# HC32F472 register map
File version: 1.0
CPU: CM4 r0p1, little endian, MPU, FPU, 4 interrupt priority bits
Registers are 32-bit, read-write, reset 0x0 unless marked. A register's access mark holds for its fields unless they carry their own. Offsets are from the block's base; [hi:lo] are bit positions; {n}, {i} and the like mark numbered series.

## TMR61 — desc TMR6
Base 0x4003C000
Same registers: TMR{n} {0x4002CC00+0x400*n} (n=62..69), TMR610 0x4003E400
0x00 CNTER (reset mask 0xFFFF)
0x04 UPDAR (reset mask 0xFFFF)
0x40 PERAR reset 0xFFFFFFFF (reset mask 0xFFFF)
0x44 PERBR reset 0xFFFFFFFF (reset mask 0xFFFF)
0x48 PERCR reset 0xFFFFFFFF (reset mask 0xFFFF)
0x80 GCMAR reset 0xFFFFFFFF (reset mask 0xFFFF)
0x84 GCMBR reset 0xFFFFFFFF (reset mask 0xFFFF)
0x88 GCMCR reset 0xFFFFFFFF (reset mask 0xFFFF)
0x8C GCMDR reset 0xFFFFFFFF (reset mask 0xFFFF)
0x90 GCMER reset 0xFFFFFFFF (reset mask 0xFFFF)
0x94 GCMFR reset 0xFFFFFFFF (reset mask 0xFFFF)
0xC0 SCMAR reset 0xFFFFFFFF (reset mask 0xFFFF)
0xC4 SCMBR reset 0xFFFFFFFF (reset mask 0xFFFF)
0xC8 SCMCR reset 0xFFFFFFFF (reset mask 0xFFFF)
0xCC SCMDR reset 0xFFFFFFFF (reset mask 0xFFFF)
0xD0 SCMER reset 0xFFFFFFFF (reset mask 0xFFFF)
0xD4 SCMFR reset 0xFFFFFFFF (reset mask 0xFFFF)
0x100 DTUAR reset 0xFFFFFFFF (reset mask 0xFFFF)
0x104 DTDAR reset 0xFFFFFFFF (reset mask 0xFFFF)
0x108 DTUBR reset 0xFFFFFFFF (reset mask 0xFFFF)
0x10C DTDBR reset 0xFFFFFFFF (reset mask 0xFFFF)
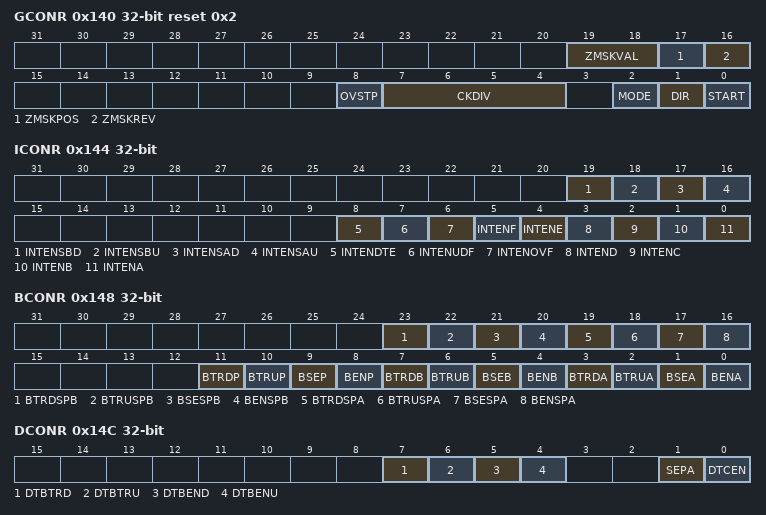
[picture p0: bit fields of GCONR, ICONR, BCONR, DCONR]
0x140 GCONR reset 0x2
  [19:18] ZMSKVAL, [17] ZMSKPOS, [16] ZMSKREV, [8] OVSTP, [7:4] CKDIV, [2] MODE, [1] DIR, [0] START
0x144 ICONR
  [19] INTENSBD, [18] INTENSBU, [17] INTENSAD, [16] INTENSAU, [8] INTENDTE, [7] INTENUDF, [6] INTENOVF, [5] INTENF, [4] INTENE, [3] INTEND, [2] INTENC, [1] INTENB, [0] INTENA
0x148 BCONR
  [23] BTRDSPB, [22] BTRUSPB, [21] BSESPB, [20] BENSPB, [19] BTRDSPA, [18] BTRUSPA, [17] BSESPA, [16] BENSPA, [11] BTRDP, [10] BTRUP, [9] BSEP, [8] BENP, [7] BTRDB, [6] BTRUB, [5] BSEB, [4] BENB, [3] BTRDA, [2] BTRUA, [1] BSEA, [0] BENA
0x14C DCONR
  [7] DTBTRD, [6] DTBTRU, [5] DTBEND, [4] DTBENU, [1] SEPA, [0] DTCEN
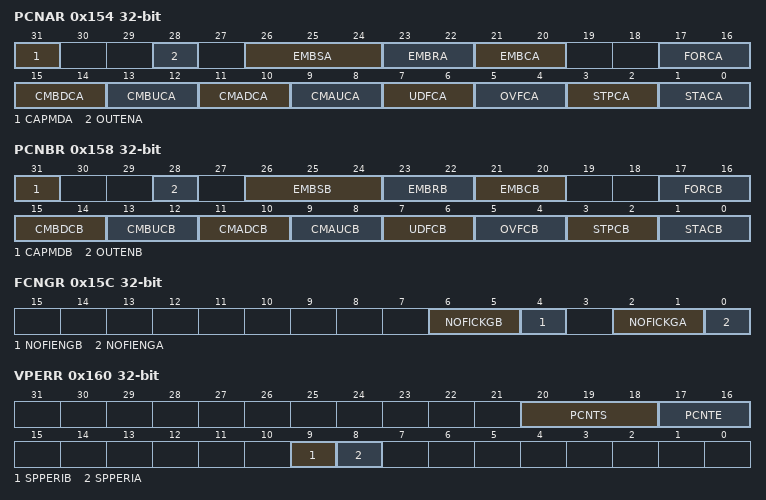
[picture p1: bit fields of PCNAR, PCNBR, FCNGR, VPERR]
0x154 PCNAR
  [31] CAPMDA, [28] OUTENA, [26:24] EMBSA, [23:22] EMBRA, [21:20] EMBCA, [17:16] FORCA, [15:14] CMBDCA, [13:12] CMBUCA, [11:10] CMADCA, [9:8] CMAUCA, [7:6] UDFCA, [5:4] OVFCA, [3:2] STPCA, [1:0] STACA
0x158 PCNBR
  [31] CAPMDB, [28] OUTENB, [26:24] EMBSB, [23:22] EMBRB, [21:20] EMBCB, [17:16] FORCB, [15:14] CMBDCB, [13:12] CMBUCB, [11:10] CMADCB, [9:8] CMAUCB, [7:6] UDFCB, [5:4] OVFCB, [3:2] STPCB, [1:0] STACB
0x15C FCNGR
  [6:5] NOFICKGB, [4] NOFIENGB, [2:1] NOFICKGA, [0] NOFIENGA
0x160 VPERR
  [20:18] PCNTS, [17:16] PCNTE, [9] SPPERIB, [8] SPPERIA
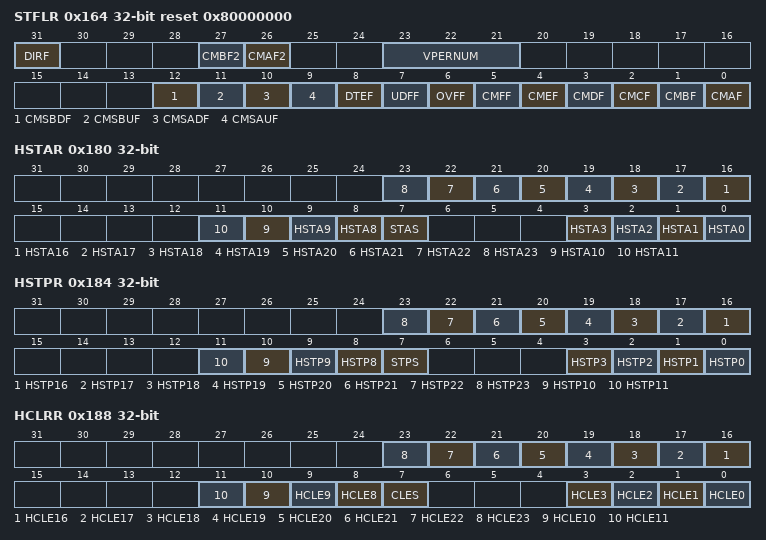
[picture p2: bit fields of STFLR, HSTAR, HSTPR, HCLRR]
0x164 STFLR reset 0x80000000
  [31] DIRF ro, [27] CMBF2, [26] CMAF2, [23:21] VPERNUM ro, [12] CMSBDF, [11] CMSBUF, [10] CMSADF, [9] CMSAUF, [8] DTEF ro, [7] UDFF, [6] OVFF, [5] CMFF, [4] CMEF, [3] CMDF, [2] CMCF, [1] CMBF, [0] CMAF
0x180 HSTAR
  [n] HSTA{n} (n=16..23), [n] HSTA{n} (n=8..11), [7] STAS, [n] HSTA{n} (n=0..3)
0x184 HSTPR
  [n] HSTP{n} (n=16..23), [n] HSTP{n} (n=8..11), [7] STPS, [n] HSTP{n} (n=0..3)
0x188 HCLRR
  [n] HCLE{n} (n=16..23), [n] HCLE{n} (n=8..11), [7] CLES, [n] HCLE{n} (n=0..3)
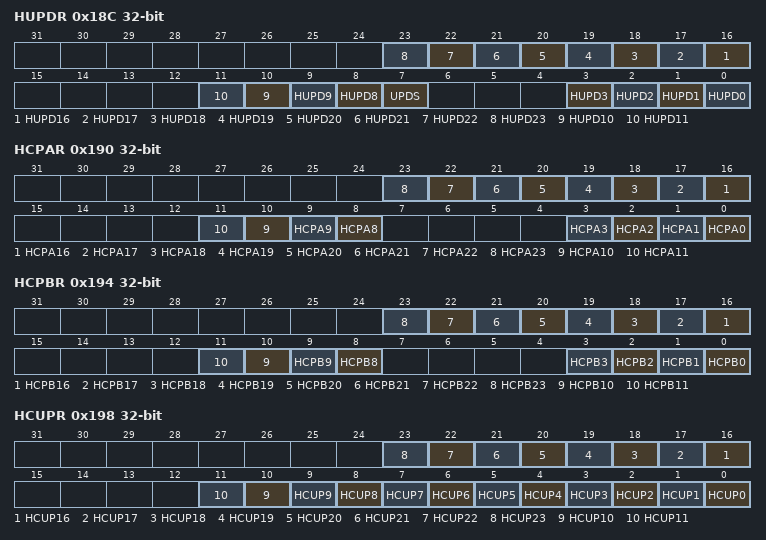
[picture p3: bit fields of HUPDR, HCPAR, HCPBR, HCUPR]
0x18C HUPDR
  [n] HUPD{n} (n=16..23), [n] HUPD{n} (n=8..11), [7] UPDS, [n] HUPD{n} (n=0..3)
0x190 HCPAR
  [n] HCPA{n} (n=16..23), [n] HCPA{n} (n=8..11), [n] HCPA{n} (n=0..3)
0x194 HCPBR
  [n] HCPB{n} (n=16..23), [n] HCPB{n} (n=8..11), [n] HCPB{n} (n=0..3)
0x198 HCUPR
  [n] HCUP{n} (n=16..23), [n] HCUP{n} (n=0..11)
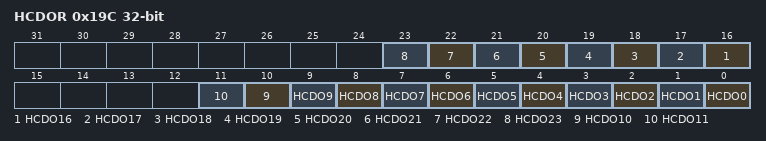
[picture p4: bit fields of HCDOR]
0x19C HCDOR
  [n] HCDO{n} (n=16..23), [n] HCDO{n} (n=0..11)

## TMR6_COMMON
Base 0x4003C300
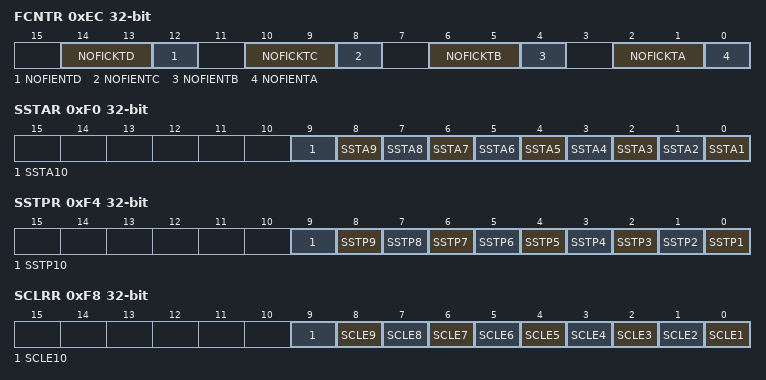
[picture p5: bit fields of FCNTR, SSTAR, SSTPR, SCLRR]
0xEC FCNTR
  [14:13] NOFICKTD, [12] NOFIENTD, [10:9] NOFICKTC, [8] NOFIENTC, [6:5] NOFICKTB, [4] NOFIENTB, [2:1] NOFICKTA, [0] NOFIENTA
0xF0 SSTAR
  [n-1] SSTA{n} (n=1..10)
0xF4 SSTPR
  [n-1] SSTP{n} (n=1..10)
0xF8 SCLRR
  [n-1] SCLE{n} (n=1..10)
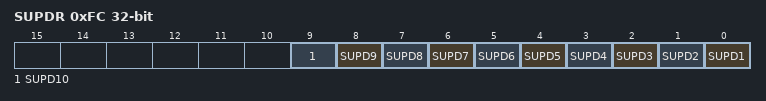
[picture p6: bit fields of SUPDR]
0xFC SUPDR
  [n-1] SUPD{n} (n=1..10)

## TMRA1
Base 0x4003A000
Same registers: TMRA2 0x4003A400
0x00 CNTER
0x04 PERAR reset 0xFFFFFFFF
{0x3C+4i} CMPAR{i} reset 0xFFFFFFFF (i=1..4)
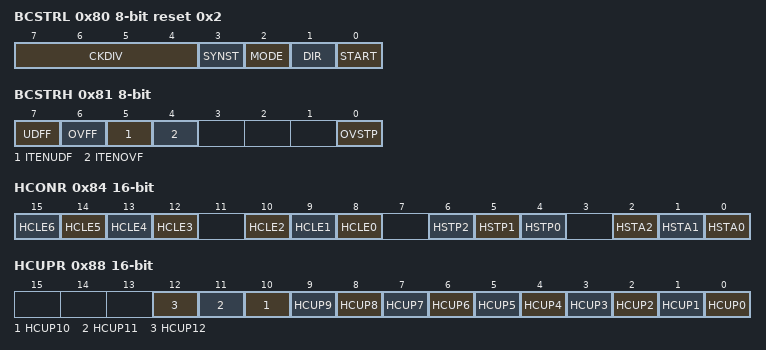
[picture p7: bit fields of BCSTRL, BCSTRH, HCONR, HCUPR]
0x80 BCSTRL 8-bit reset 0x2
  [7:4] CKDIV, [3] SYNST, [2] MODE, [1] DIR, [0] START
0x81 BCSTRH 8-bit
  [7] UDFF, [6] OVFF, [5] ITENUDF, [4] ITENOVF, [0] OVSTP
0x84 HCONR 16-bit
  [n+9] HCLE{n} (n=3..6), [10] HCLE2, [9] HCLE1, [8] HCLE0, [6] HSTP2, [5] HSTP1, [4] HSTP0, [2] HSTA2, [1] HSTA1, [0] HSTA0
0x88 HCUPR 16-bit
  [n] HCUP{n} (n=0..12)
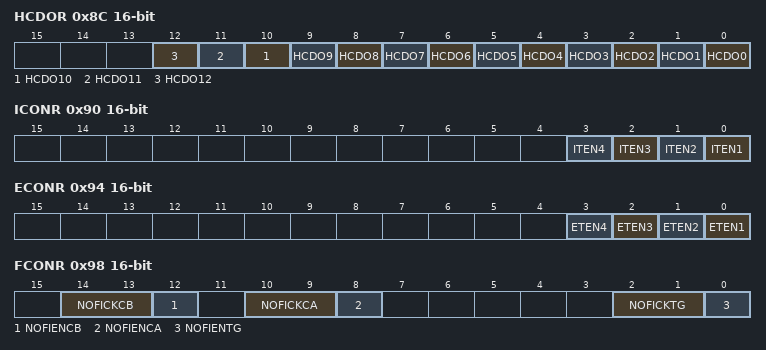
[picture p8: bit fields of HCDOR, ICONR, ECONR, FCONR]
0x8C HCDOR 16-bit
  [n] HCDO{n} (n=0..12)
0x90 ICONR 16-bit
  [n-1] ITEN{n} (n=1..4)
0x94 ECONR 16-bit
  [n-1] ETEN{n} (n=1..4)
0x98 FCONR 16-bit
  [14:13] NOFICKCB, [12] NOFIENCB, [10:9] NOFICKCA, [8] NOFIENCA, [2:1] NOFICKTG, [0] NOFIENTG
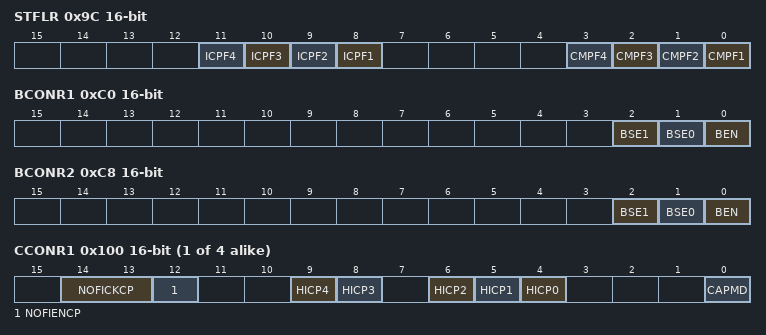
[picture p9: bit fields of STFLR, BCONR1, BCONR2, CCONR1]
0x9C STFLR 16-bit
  [n+7] ICPF{n} (n=1..4), [n-1] CMPF{n} (n=1..4)
0xC0 BCONR1 16-bit
  [2] BSE1, [1] BSE0, [0] BEN
0xC8 BCONR2 16-bit
  [2] BSE1, [1] BSE0, [0] BEN
{0xFC+4i} CCONR{i} 16-bit (i=1..4)
  [14:13] NOFICKCP, [12] NOFIENCP, [9] HICP4, [8] HICP3, [6] HICP2, [5] HICP1, [4] HICP0, [0] CAPMD
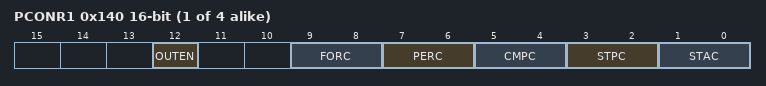
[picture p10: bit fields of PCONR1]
{0x13C+4i} PCONR{i} 16-bit (i=1..4)
  [12] OUTEN, [9:8] FORC, [7:6] PERC, [5:4] CMPC, [3:2] STPC, [1:0] STAC

## TMRA3
Base 0x4003A800
Same registers: TMRA5 0x40026000, TMRA6 0x40026400, TMRA4 0x4003AC00
Registers as TMRA1; these are added or differ:
0x00 CNTER 16-bit
0x04 PERAR 16-bit reset 0xFFFF
{0x3C+4i} CMPAR{i} 16-bit reset 0xFFFF (i=1..4)

## TRNG
Base 0x40042000
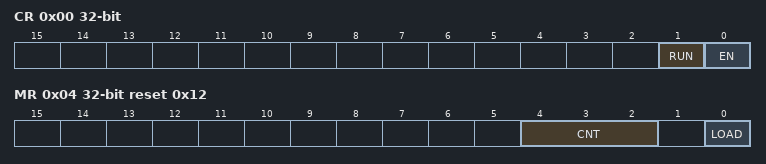
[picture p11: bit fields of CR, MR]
0x00 CR
  [1] RUN, [0] EN
0x04 MR reset 0x12
  [4:2] CNT, [0] LOAD
0x0C DR0 ro reset 0x8000000
0x10 DR1 ro reset 0x8000200

## USART1
Base 0x4001CC00
Same registers: USART2 0x4001D000, USART4 0x40020C00, USART5 0x40021000
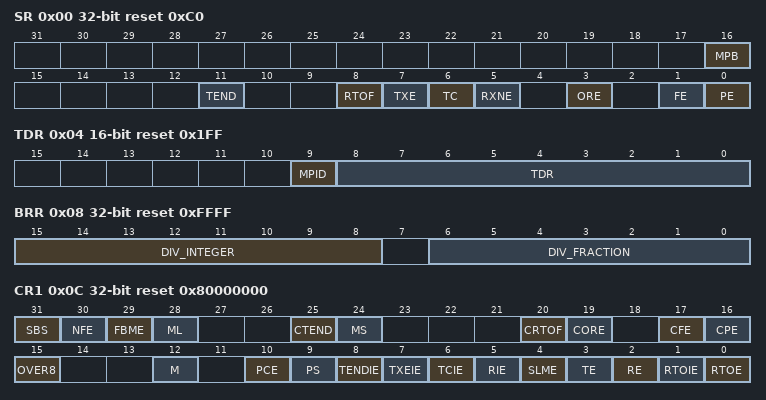
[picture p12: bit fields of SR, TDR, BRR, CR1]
0x00 SR ro reset 0xC0
  [16] MPB, [11] TEND, [8] RTOF, [7] TXE, [6] TC, [5] RXNE, [3] ORE, [1] FE, [0] PE
0x04 TDR 16-bit reset 0x1FF
  [9] MPID, [8:0] TDR
0x06 RDR 16-bit ro
  [8:0] RDR
0x08 BRR reset 0xFFFF
  [15:8] DIV_INTEGER, [6:0] DIV_FRACTION
0x0C CR1 reset 0x80000000
  [31] SBS, [30] NFE, [29] FBME, [28] ML, [25] CTEND, [24] MS, [20] CRTOF, [19] CORE, [17] CFE, [16] CPE, [15] OVER8, [12] M, [10] PCE, [9] PS, [8] TENDIE, [7] TXEIE, [6] TCIE, [5] RIE, [4] SLME, [3] TE, [2] RE, [1] RTOIE, [0] RTOE
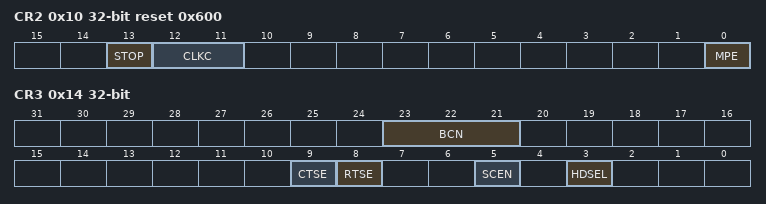
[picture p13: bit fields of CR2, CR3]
0x10 CR2 reset 0x600
  [13] STOP, [12:11] CLKC, [0] MPE
0x14 CR3
  [23:21] BCN, [9] CTSE, [8] RTSE, [5] SCEN, [3] HDSEL
0x18 PR
  [1:0] PSC

## USART3
Base 0x4001D400
Same registers: USART6 0x40021400
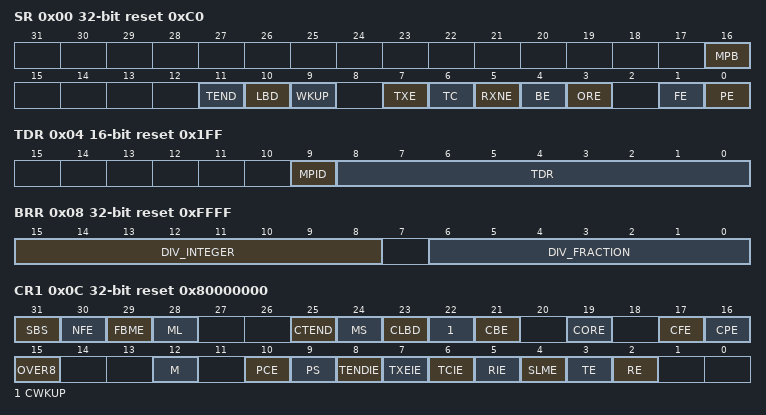
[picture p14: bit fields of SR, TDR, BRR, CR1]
0x00 SR ro reset 0xC0
  [16] MPB, [11] TEND, [10] LBD, [9] WKUP, [7] TXE, [6] TC, [5] RXNE, [4] BE, [3] ORE, [1] FE, [0] PE
0x04 TDR 16-bit reset 0x1FF
  [9] MPID, [8:0] TDR
0x06 RDR 16-bit ro
  [8:0] RDR
0x08 BRR reset 0xFFFF
  [15:8] DIV_INTEGER, [6:0] DIV_FRACTION
0x0C CR1 reset 0x80000000
  [31] SBS, [30] NFE, [29] FBME, [28] ML, [25] CTEND, [24] MS, [23] CLBD, [22] CWKUP, [21] CBE, [19] CORE, [17] CFE, [16] CPE, [15] OVER8, [12] M, [10] PCE, [9] PS, [8] TENDIE, [7] TXEIE, [6] TCIE, [5] RIE, [4] SLME, [3] TE, [2] RE
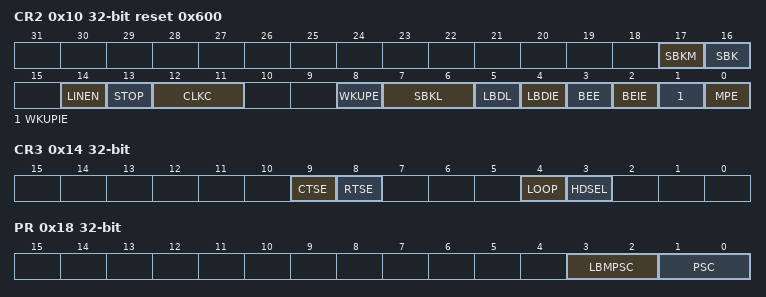
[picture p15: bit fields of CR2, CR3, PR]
0x10 CR2 reset 0x600
  [17] SBKM, [16] SBK, [14] LINEN, [13] STOP, [12:11] CLKC, [8] WKUPE, [7:6] SBKL, [5] LBDL, [4] LBDIE, [3] BEE, [2] BEIE, [1] WKUPIE, [0] MPE
0x14 CR3
  [9] CTSE, [8] RTSE, [4] LOOP, [3] HDSEL
0x18 PR
  [3:2] LBMPSC, [1:0] PSC
0x1C LBMC ro
  [15:0] LBMC

## VREF
Base 0x4004F800
0x00 BGRCR
  [0] BGREN
0x04 CSCR
  [0] CSEN
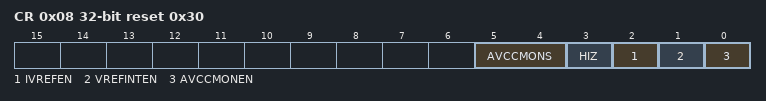
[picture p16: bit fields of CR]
0x08 CR reset 0x30
  [5:4] AVCCMONS, [3] HIZ, [2] IVREFEN, [1] VREFINTEN, [0] AVCCMONEN
